AUTOSAR XML (schema 4-2-1)
package /MICROSAR/WdgM_swc/ComponentTypes
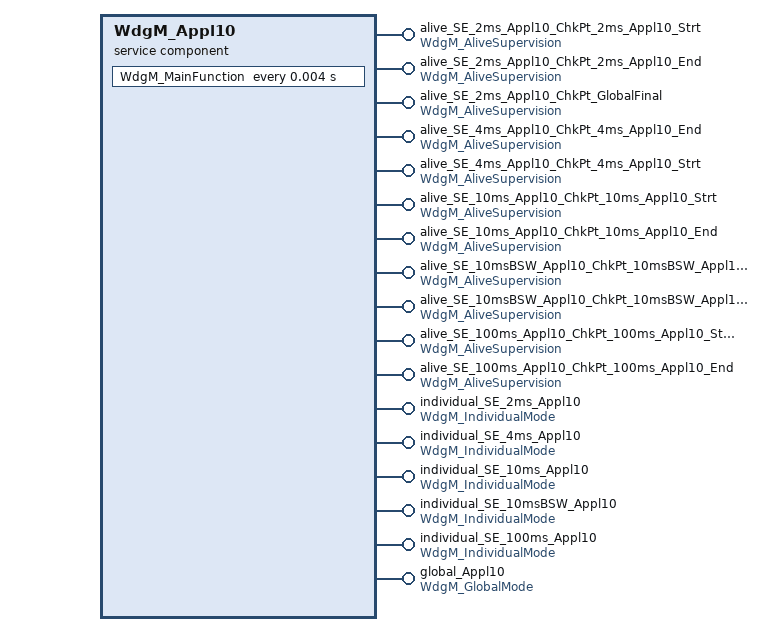
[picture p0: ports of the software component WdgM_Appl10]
  service sw component type WdgM_Appl10: category=SERVICE_COMPONENT
    17 x provide port:
      alive_SE_2ms_Appl10_ChkPt_2ms_Appl10_Strt: provided-interface=WdgM_AliveSupervision  # Alive-P-Port Prototype for supervised entity 'SE_2ms_Appl10' with Id '1' for Application 'Appl10'.
      alive_SE_2ms_Appl10_ChkPt_2ms_Appl10_End: provided-interface=WdgM_AliveSupervision  # Alive-P-Port Prototype for supervised entity 'SE_2ms_Appl10' with Id '1' for Application 'Appl10'.
      alive_SE_2ms_Appl10_ChkPt_GlobalFinal: provided-interface=WdgM_AliveSupervision  # Alive-P-Port Prototype for supervised entity 'SE_2ms_Appl10' with Id '1' for Application 'Appl10'.
      alive_SE_4ms_Appl10_ChkPt_4ms_Appl10_End: provided-interface=WdgM_AliveSupervision  # Alive-P-Port Prototype for supervised entity 'SE_4ms_Appl10' with Id '2' for Application 'Appl10'.
      alive_SE_4ms_Appl10_ChkPt_4ms_Appl10_Strt: provided-interface=WdgM_AliveSupervision  # Alive-P-Port Prototype for supervised entity 'SE_4ms_Appl10' with Id '2' for Application 'Appl10'.
      alive_SE_10ms_Appl10_ChkPt_10ms_Appl10_Strt: provided-interface=WdgM_AliveSupervision  # Alive-P-Port Prototype for supervised entity 'SE_10ms_Appl10' with Id '3' for Application 'Appl10'.
      alive_SE_10ms_Appl10_ChkPt_10ms_Appl10_End: provided-interface=WdgM_AliveSupervision  # Alive-P-Port Prototype for supervised entity 'SE_10ms_Appl10' with Id '3' for Application 'Appl10'.
      alive_SE_10msBSW_Appl10_ChkPt_10msBSW_Appl10_Strt: provided-interface=WdgM_AliveSupervision  # Alive-P-Port Prototype for supervised entity 'SE_10msBSW_Appl10' with Id '0' for Application 'Appl10'.
      alive_SE_10msBSW_Appl10_ChkPt_10msBSW_Appl10_End: provided-interface=WdgM_AliveSupervision  # Alive-P-Port Prototype for supervised entity 'SE_10msBSW_Appl10' with Id '0' for Application 'Appl10'.
      alive_SE_100ms_Appl10_ChkPt_100ms_Appl10_Strt: provided-interface=WdgM_AliveSupervision  # Alive-P-Port Prototype for supervised entity 'SE_100ms_Appl10' with Id '4' for Application 'Appl10'.
      alive_SE_100ms_Appl10_ChkPt_100ms_Appl10_End: provided-interface=WdgM_AliveSupervision  # Alive-P-Port Prototype for supervised entity 'SE_100ms_Appl10' with Id '4' for Application 'Appl10'.
      individual_SE_2ms_Appl10: provided-interface=WdgM_IndividualMode  # IndividualMode-P-Port Prototype for supervised entity 'SE_2ms_Appl10' with Id '1' for Application 'Appl10'.
      individual_SE_4ms_Appl10: provided-interface=WdgM_IndividualMode  # IndividualMode-P-Port Prototype for supervised entity 'SE_4ms_Appl10' with Id '2' for Application 'Appl10'.
      individual_SE_10ms_Appl10: provided-interface=WdgM_IndividualMode  # IndividualMode-P-Port Prototype for supervised entity 'SE_10ms_Appl10' with Id '3' for Application 'Appl10'.
      individual_SE_10msBSW_Appl10: provided-interface=WdgM_IndividualMode  # IndividualMode-P-Port Prototype for supervised entity 'SE_10msBSW_Appl10' with Id '0' for Application 'Appl10'.
      individual_SE_100ms_Appl10: provided-interface=WdgM_IndividualMode  # IndividualMode-P-Port Prototype for supervised entity 'SE_100ms_Appl10' with Id '4' for Application 'Appl10'.
      global_Appl10: provided-interface=WdgM_GlobalMode  # Global-P-Port-Prototype for core 0 (Appl10)
    behavior WdgM_Appl10InternalBehavior: handle-termination-and-restart=NO-SUPPORT
      timing event Timer_WdgM_MainFunction: start-on-event=WdgM_MainFunction, period=0.004
      24 x operation invoked event:
        OpEventCheckpointReached_CheckpointReached_alive_SE_2ms_Appl10_ChkPt_2ms_Appl10_Strt: start-on-event=CheckpointReached, operation=alive_SE_2ms_Appl10_ChkPt_2ms_Appl10_Strt.CheckpointReached
        OpEventCheckpointReached_CheckpointReached_alive_SE_2ms_Appl10_ChkPt_2ms_Appl10_End: start-on-event=CheckpointReached, operation=alive_SE_2ms_Appl10_ChkPt_2ms_Appl10_End.CheckpointReached
        OpEventCheckpointReached_CheckpointReached_alive_SE_2ms_Appl10_ChkPt_GlobalFinal: start-on-event=CheckpointReached, operation=alive_SE_2ms_Appl10_ChkPt_GlobalFinal.CheckpointReached
        OpEventCheckpointReached_CheckpointReached_alive_SE_4ms_Appl10_ChkPt_4ms_Appl10_End: start-on-event=CheckpointReached, operation=alive_SE_4ms_Appl10_ChkPt_4ms_Appl10_End.CheckpointReached
        OpEventCheckpointReached_CheckpointReached_alive_SE_4ms_Appl10_ChkPt_4ms_Appl10_Strt: start-on-event=CheckpointReached, operation=alive_SE_4ms_Appl10_ChkPt_4ms_Appl10_Strt.CheckpointReached
        OpEventCheckpointReached_CheckpointReached_alive_SE_10ms_Appl10_ChkPt_10ms_Appl10_Strt: start-on-event=CheckpointReached, operation=alive_SE_10ms_Appl10_ChkPt_10ms_Appl10_Strt.CheckpointReached
        OpEventCheckpointReached_CheckpointReached_alive_SE_10ms_Appl10_ChkPt_10ms_Appl10_End: start-on-event=CheckpointReached, operation=alive_SE_10ms_Appl10_ChkPt_10ms_Appl10_End.CheckpointReached
        OpEventCheckpointReached_CheckpointReached_alive_SE_10msBSW_Appl10_ChkPt_10msBSW_Appl10_Strt: start-on-event=CheckpointReached, operation=alive_SE_10msBSW_Appl10_ChkPt_10msBSW_Appl10_Strt.CheckpointReached
        OpEventCheckpointReached_CheckpointReached_alive_SE_10msBSW_Appl10_ChkPt_10msBSW_Appl10_End: start-on-event=CheckpointReached, operation=alive_SE_10msBSW_Appl10_ChkPt_10msBSW_Appl10_End.CheckpointReached
        OpEventCheckpointReached_CheckpointReached_alive_SE_100ms_Appl10_ChkPt_100ms_Appl10_Strt: start-on-event=CheckpointReached, operation=alive_SE_100ms_Appl10_ChkPt_100ms_Appl10_Strt.CheckpointReached
        OpEventCheckpointReached_CheckpointReached_alive_SE_100ms_Appl10_ChkPt_100ms_Appl10_End: start-on-event=CheckpointReached, operation=alive_SE_100ms_Appl10_ChkPt_100ms_Appl10_End.CheckpointReached
        OpEventGetLocalStatus_GetLocalStatus_individual_SE_2ms_Appl10: start-on-event=GetLocalStatus, operation=individual_SE_2ms_Appl10.GetLocalStatus
        OpEventGetLocalStatus_GetLocalStatus_individual_SE_4ms_Appl10: start-on-event=GetLocalStatus, operation=individual_SE_4ms_Appl10.GetLocalStatus
        OpEventGetLocalStatus_GetLocalStatus_individual_SE_10ms_Appl10: start-on-event=GetLocalStatus, operation=individual_SE_10ms_Appl10.GetLocalStatus
        OpEventGetLocalStatus_GetLocalStatus_individual_SE_10msBSW_Appl10: start-on-event=GetLocalStatus, operation=individual_SE_10msBSW_Appl10.GetLocalStatus
        OpEventGetLocalStatus_GetLocalStatus_individual_SE_100ms_Appl10: start-on-event=GetLocalStatus, operation=individual_SE_100ms_Appl10.GetLocalStatus
        OpEventGetLocalStatus_GetLocalStatus_global_Appl10: start-on-event=GetLocalStatus, operation=global_Appl10.GetLocalStatus
        OpEventGetMode_GetMode_global_Appl10: start-on-event=GetMode, operation=global_Appl10.GetMode
        OpEventGetGlobalStatus_GetGlobalStatus_global_Appl10: start-on-event=GetGlobalStatus, operation=global_Appl10.GetGlobalStatus
        OpEventPerformReset_PerformReset_global_Appl10: start-on-event=PerformReset, operation=global_Appl10.PerformReset
        OpEventSetMode_SetMode_global_Appl10: start-on-event=SetMode, operation=global_Appl10.SetMode
        OpEventGetFirstExpiredSEID_GetFirstExpiredSEID_global_Appl10: start-on-event=GetFirstExpiredSEID, operation=global_Appl10.GetFirstExpiredSEID
        OpEventActivateSupervisionEntity_ActivateSupervisionEntity_global_Appl10: start-on-event=ActivateSupervisionEntity, operation=global_Appl10.ActivateSupervisionEntity
        OpEventDeactivateSupervisionEntity_DeactivateSupervisionEntity_global_Appl10: start-on-event=DeactivateSupervisionEntity, operation=global_Appl10.DeactivateSupervisionEntity
      port-api-options:
        {enable-take-address=true, indirect-api=false, port-arg-values=[{value=1, value-type=WdgM_SupervisedEntityIdType}, {value=0, value-type=WdgM_CheckpointIdType}], port=alive_SE_2ms_Appl10_ChkPt_2ms_Appl10_Strt}
        {enable-take-address=true, indirect-api=false, port-arg-values=[{value=1, value-type=WdgM_SupervisedEntityIdType}, {value=1, value-type=WdgM_CheckpointIdType}], port=alive_SE_2ms_Appl10_ChkPt_2ms_Appl10_End}
        {enable-take-address=true, indirect-api=false, port-arg-values=[{value=1, value-type=WdgM_SupervisedEntityIdType}, {value=2, value-type=WdgM_CheckpointIdType}], port=alive_SE_2ms_Appl10_ChkPt_GlobalFinal}
        {enable-take-address=true, indirect-api=false, port-arg-values=[{value=2, value-type=WdgM_SupervisedEntityIdType}, {value=1, value-type=WdgM_CheckpointIdType}], port=alive_SE_4ms_Appl10_ChkPt_4ms_Appl10_End}
        {enable-take-address=true, indirect-api=false, port-arg-values=[{value=2, value-type=WdgM_SupervisedEntityIdType}, {value=0, value-type=WdgM_CheckpointIdType}], port=alive_SE_4ms_Appl10_ChkPt_4ms_Appl10_Strt}
        {enable-take-address=true, indirect-api=false, port-arg-values=[{value=3, value-type=WdgM_SupervisedEntityIdType}, {value=0, value-type=WdgM_CheckpointIdType}], port=alive_SE_10ms_Appl10_ChkPt_10ms_Appl10_Strt}
        {enable-take-address=true, indirect-api=false, port-arg-values=[{value=3, value-type=WdgM_SupervisedEntityIdType}, {value=1, value-type=WdgM_CheckpointIdType}], port=alive_SE_10ms_Appl10_ChkPt_10ms_Appl10_End}
        {enable-take-address=true, indirect-api=false, port-arg-values=[{value=0, value-type=WdgM_SupervisedEntityIdType}, {value=0, value-type=WdgM_CheckpointIdType}], port=alive_SE_10msBSW_Appl10_ChkPt_10msBSW_Appl10_Strt}
        {enable-take-address=true, indirect-api=false, port-arg-values=[{value=0, value-type=WdgM_SupervisedEntityIdType}, {value=1, value-type=WdgM_CheckpointIdType}], port=alive_SE_10msBSW_Appl10_ChkPt_10msBSW_Appl10_End}
        {enable-take-address=true, indirect-api=false, port-arg-values=[{value=4, value-type=WdgM_SupervisedEntityIdType}, {value=0, value-type=WdgM_CheckpointIdType}], port=alive_SE_100ms_Appl10_ChkPt_100ms_Appl10_Strt}
        {enable-take-address=true, indirect-api=false, port-arg-values=[{value=4, value-type=WdgM_SupervisedEntityIdType}, {value=1, value-type=WdgM_CheckpointIdType}], port=alive_SE_100ms_Appl10_ChkPt_100ms_Appl10_End}
        {enable-take-address=true, indirect-api=false, port-defined-argument-value{value=1, value-type=WdgM_SupervisedEntityIdType}, port=individual_SE_2ms_Appl10}
        {enable-take-address=true, indirect-api=false, port-defined-argument-value{value=2, value-type=WdgM_SupervisedEntityIdType}, port=individual_SE_4ms_Appl10}
        {enable-take-address=true, indirect-api=false, port-defined-argument-value{value=3, value-type=WdgM_SupervisedEntityIdType}, port=individual_SE_10ms_Appl10}
        {enable-take-address=true, indirect-api=false, port-defined-argument-value{value=0, value-type=WdgM_SupervisedEntityIdType}, port=individual_SE_10msBSW_Appl10}
        {enable-take-address=true, indirect-api=false, port-defined-argument-value{value=4, value-type=WdgM_SupervisedEntityIdType}, port=individual_SE_100ms_Appl10}
        enable-take-address=true, indirect-api=false, port=global_Appl10
      10 x runnable, all with can-be-invoked-concurrently=true:
        WdgM_MainFunction
        CheckpointReached: symbol=WdgM_CheckpointReached
        GetLocalStatus: symbol=WdgM_GetLocalStatus
        GetMode: symbol=WdgM_GetMode
        GetGlobalStatus: symbol=WdgM_GetGlobalStatus
        PerformReset: symbol=WdgM_PerformReset
        SetMode: symbol=WdgM_SetMode
        GetFirstExpiredSEID: symbol=WdgM_GetFirstExpiredSEID
        ActivateSupervisionEntity: symbol=WdgM_ActivateSupervisionEntity
        DeactivateSupervisionEntity: symbol=WdgM_DeactivateSupervisionEntity
  swc implementation WdgM_Appl10Implementation: programming-language=C, behavior=WdgM_Appl10InternalBehavior
package /MICROSAR/WdgM_swc/DataTypes
  5 x impl type, all with category=TYPE_REFERENCE:
    WdgM_SupervisedEntityIdType: range raw 0..65535, implementation-data-type=uint16  # Identifier of a supervised entity
    WdgM_CheckpointIdType: range raw 0..65535, implementation-data-type=uint16  # Identifier of a checkpoint
    WdgM_ModeType: range raw 0..255, implementation-data-type=uint8  # Identifier of the Watchdog trigger mode
    WdgM_LocalStatusType: compu {0=WDGM_LOCAL_STATUS_OK, 1=WDGM_LOCAL_STATUS_FAILED, 2=WDGM_LOCAL_STATUS_EXPIRED, 4=WDGM_LOCAL_STATUS_DEACTIVATED}, implementation-data-type=uint8  # Local Monitoring Status of a supervised entity.
    WdgM_GlobalStatusType: compu {0=WDGM_GLOBAL_STATUS_OK, 1=WDGM_GLOBAL_STATUS_FAILED, 2=WDGM_GLOBAL_STATUS_EXPIRED, 3=WDGM_GLOBAL_STATUS_STOPPED, 4=WDGM_GLOBAL_STATUS_DEACTIVATED}, implementation-data-type=uint8  # Global Monitoring Status summarizes all local monitoring statuses of all supervised entities.
package /MICROSAR/WdgM_swc/Interfaces
  client server interface WdgM_AliveSupervision: is-service=true, service-kind=WATCH-DOG-MANAGER
    operation CheckpointReached: possible-error=WdgM_AliveSupervision/E_NOT_OK  # Indicates to the Watchdog Manager that a Checkpoint within a Supervised Entity has been reached.
    error E_NOT_OK: error-code=1
  client server interface WdgM_IndividualMode: is-service=true, service-kind=WATCH-DOG-MANAGER
    operation GetLocalStatus: possible-error=WdgM_IndividualMode/E_NOT_OK  # Returns the supervision status of an individual supervised entity.
      arg Status: type=WdgM_LocalStatusType, direction=OUT  # Supervision status of the given supervised entity.
    error E_NOT_OK: error-code=1
  client server interface WdgM_GlobalMode: is-service=true, service-kind=WATCH-DOG-MANAGER
    8 x operation, all with possible-error=WdgM_GlobalMode/E_NOT_OK:
      GetMode  # Returns the current mode of the Watchdog Manager.
        arg Mode: type=WdgM_ModeType, direction=OUT  # Current mode of the Watchdog Manager.
      GetGlobalStatus  # Returns the global supervision status of the Watchdog Manager.
        arg Status: type=WdgM_GlobalStatusType, direction=OUT  # Global supervision status of the Watchdog Manager.
      GetLocalStatus  # Returns the supervision status of a supervised entity.
        arg SEID: type=WdgM_SupervisedEntityIdType, direction=IN  # Identifier of the supervised entity whose supervision status shall be returned.
        arg Status: type=WdgM_LocalStatusType, direction=OUT  # Supervision status of the given supervised entity.
      PerformReset  # Instructs the Watchdog Manager to cause a watchdog reset.
      SetMode  # Requests a new trigger mode
        arg Mode: type=WdgM_ModeType, direction=IN  # Desired new trigger mode id.
      GetFirstExpiredSEID  # Returns the id of that supervised entity which first reached the status WDGM_LOCAL_STATUS_EXPIRED.
        arg SEID: type=WdgM_SupervisedEntityIdType, direction=OUT  # Pointer to a variable that stores the id of the supervised entity.
      ActivateSupervisionEntity  # Activates the supervision of the given supervised entity.
        arg SEID: type=WdgM_SupervisedEntityIdType, direction=IN  # Identifier of the supervised entity whose supervision shall be enabled.
      DeactivateSupervisionEntity  # Deactivates the supervision of the given supervised entity.
        arg SEID: type=WdgM_SupervisedEntityIdType, direction=IN  # Identifier of the supervised entity whose supervision shall be disenabled.
    error E_NOT_OK: error-code=1
